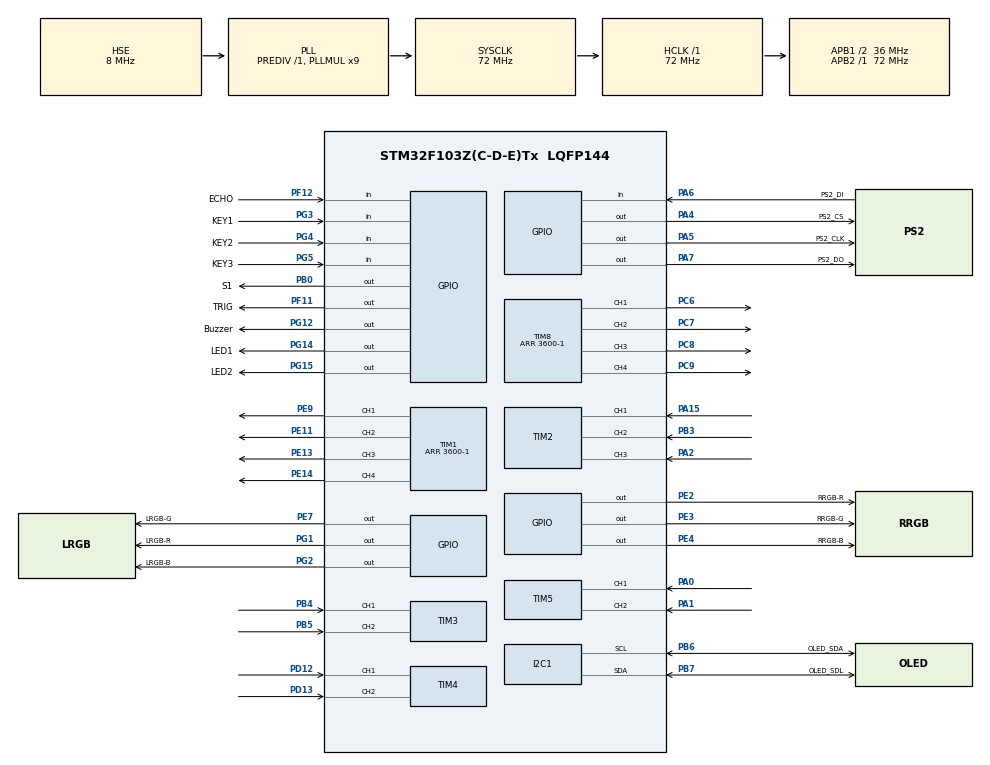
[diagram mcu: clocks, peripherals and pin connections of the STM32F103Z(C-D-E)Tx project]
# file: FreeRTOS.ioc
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ADC1.Channel-0\#ChannelRegularConversion=ADC_CHANNEL_TEMPSENSOR
ADC1.NbrOfConversionFlag=1
ADC1.Rank-0\#ChannelRegularConversion=1
ADC1.SamplingTime-0\#ChannelRegularConversion=ADC_SAMPLETIME_1CYCLE_5
ADC1.master=1
FREERTOS.Tasks01=defaultTask,0,128,StartDefaultTask,Default,NULL,Dynamic,NULL,NULL
FREERTOS.configTOTAL_HEAP_SIZE=20 * 1024
I2C1.I2C_Mode=I2C_Standard
Mcu.Family=STM32F1
Mcu.Name=STM32F103Z(C-D-E)Tx
Mcu.Package=LQFP144
NVIC.PriorityGroup=NVIC_PRIORITYGROUP_4
NVIC.TIM6_IRQn=true\:15\:0\:false\:false\:true\:false\:false\:true\:true
NVIC.TIM7_IRQn=true\:5\:0\:false\:false\:true\:true\:true\:true\:true
NVIC.TimeBase=TIM6_IRQn
NVIC.TimeBaseIP=TIM6
OSC_IN.Mode=HSE-External-Oscillator
OSC_IN.Signal=RCC_OSC_IN
OSC_OUT.Mode=HSE-External-Oscillator
OSC_OUT.Signal=RCC_OSC_OUT
PA0-WKUP.Signal=S_TIM5_CH1
PA1.Signal=S_TIM5_CH2
PA13.Mode=Serial_Wire
PA13.Signal=SYS_JTMS-SWDIO
PA14.Mode=Serial_Wire
PA14.Signal=SYS_JTCK-SWCLK
PA15.Signal=S_TIM2_CH1_ETR
PA2.Signal=S_TIM2_CH3
PA4.GPIO_Label=PS2_CS
PA4.GPIO_Speed=GPIO_SPEED_FREQ_MEDIUM
PA4.Signal=GPIO_Output
PA5.GPIO_Label=PS2_CLK
PA5.GPIO_Speed=GPIO_SPEED_FREQ_MEDIUM
PA5.PinState=GPIO_PIN_RESET
PA5.Signal=GPIO_Output
PA6.GPIO_Label=PS2_DI
PA6.Signal=GPIO_Input
PA7.GPIO_Label=PS2_DO
PA7.GPIO_Speed=GPIO_SPEED_FREQ_MEDIUM
PA7.Signal=GPIO_Output
PB0.GPIO_Label=S1
PB0.Signal=GPIO_Output
PB3.Signal=S_TIM2_CH2
PB4.Signal=S_TIM3_CH1
PB5.Signal=S_TIM3_CH2
PB6.GPIO_Label=OLED_SDA
PB6.Mode=I2C
PB6.Signal=I2C1_SCL
PB7.GPIO_Label=OLED_SDL
PB7.Mode=I2C
PB7.Signal=I2C1_SDA
PC6.Signal=S_TIM8_CH1
PC7.Signal=S_TIM8_CH2
PC8.Signal=S_TIM8_CH3
PC9.Signal=S_TIM8_CH4
PD12.Signal=S_TIM4_CH1
PD13.Signal=S_TIM4_CH2
PE11.Signal=S_TIM1_CH2
PE13.Signal=S_TIM1_CH3
PE14.Signal=S_TIM1_CH4
PE2.GPIO_Label=RRGB-R
PE2.Signal=GPIO_Output
PE3.GPIO_Label=RRGB-G
PE3.Signal=GPIO_Output
PE4.GPIO_Label=RRGB-B
PE4.Signal=GPIO_Output
PE7.GPIO_Label=LRGB-G
PE7.Signal=GPIO_Output
PE9.Signal=S_TIM1_CH1
PF11.GPIO_Label=TRIG
PF11.GPIO_Speed=GPIO_SPEED_FREQ_HIGH
PF11.PinState=GPIO_PIN_SET
PF11.Signal=GPIO_Output
PF12.GPIO_Label=ECHO
PF12.Signal=GPIO_Input
PG1.GPIO_Label=LRGB-R
PG1.Signal=GPIO_Output
PG12.GPIO_Label=Buzzer
PG12.Signal=GPIO_Output
PG14.GPIO_Label=LED1
PG14.Signal=GPIO_Output
PG15.GPIO_Label=LED2
PG15.Signal=GPIO_Output
PG2.GPIO_Label=LRGB-B
PG2.Signal=GPIO_Output
PG3.GPIO_Label=KEY1
PG3.Signal=GPIO_Input
PG4.GPIO_Label=KEY2
PG4.Signal=GPIO_Input
PG5.GPIO_Label=KEY3
PG5.Signal=GPIO_Input
ProjectManager.HeapSize=0x200
ProjectManager.StackSize=0x400
ProjectManager.TargetToolchain=STM32CubeIDE
RCC.AHBFreq_Value=72000000
RCC.APB1CLKDivider=RCC_HCLK_DIV2
RCC.APB1Freq_Value=36000000
RCC.APB1TimFreq_Value=72000000
RCC.APB2Freq_Value=72000000
RCC.APB2TimFreq_Value=72000000
RCC.HCLKFreq_Value=72000000
RCC.PLLMUL=RCC_PLL_MUL9
RCC.PLLSourceVirtual=RCC_PLLSOURCE_HSE
RCC.SYSCLKFreq_VALUE=72000000
RCC.SYSCLKSource=RCC_SYSCLKSOURCE_PLLCLK
RCC.USBFreq_Value=72000000
SH.S_TIM1_CH1.0=TIM1_CH1,PWM Generation1 CH1
SH.S_TIM1_CH2.0=TIM1_CH2,PWM Generation2 CH2
SH.S_TIM1_CH3.0=TIM1_CH3,PWM Generation3 CH3
SH.S_TIM1_CH4.0=TIM1_CH4,PWM Generation4 CH4
SH.S_TIM2_CH1_ETR.0=TIM2_CH1,Encoder_Interface
SH.S_TIM2_CH2.0=TIM2_CH2,Encoder_Interface
SH.S_TIM2_CH3.0=TIM2_CH3,Input_Capture3_from_TI3
SH.S_TIM3_CH1.0=TIM3_CH1,Encoder_Interface
SH.S_TIM3_CH2.0=TIM3_CH2,Encoder_Interface
SH.S_TIM4_CH1.0=TIM4_CH1,Encoder_Interface
SH.S_TIM4_CH2.0=TIM4_CH2,Encoder_Interface
SH.S_TIM5_CH1.0=TIM5_CH1,Encoder_Interface
SH.S_TIM5_CH2.0=TIM5_CH2,Encoder_Interface
SH.S_TIM8_CH1.0=TIM8_CH1,PWM Generation1 CH1
SH.S_TIM8_CH2.0=TIM8_CH2,PWM Generation2 CH2
SH.S_TIM8_CH3.0=TIM8_CH3,PWM Generation3 CH3
SH.S_TIM8_CH4.0=TIM8_CH4,PWM Generation4 CH4
TIM1.AutoReloadPreload=TIM_AUTORELOAD_PRELOAD_ENABLE
TIM1.Channel-PWM\ Generation1\ CH1=TIM_CHANNEL_1
TIM1.Channel-PWM\ Generation2\ CH2=TIM_CHANNEL_2
TIM1.Channel-PWM\ Generation3\ CH3=TIM_CHANNEL_3
TIM1.Channel-PWM\ Generation4\ CH4=TIM_CHANNEL_4
TIM1.Period=3600-1
TIM2.Channel-Input_Capture3_from_TI3=TIM_CHANNEL_3
TIM2.EncoderMode=TIM_ENCODERMODE_TI12
TIM3.EncoderMode=TIM_ENCODERMODE_TI12
TIM4.EncoderMode=TIM_ENCODERMODE_TI12
TIM5.EncoderMode=TIM_ENCODERMODE_TI12
TIM7.AutoReloadPreload=TIM_AUTORELOAD_PRELOAD_DISABLE
TIM7.Period=9
TIM7.Prescaler=71
TIM8.AutoReloadPreload=TIM_AUTORELOAD_PRELOAD_ENABLE
TIM8.Channel-PWM\ Generation1\ CH1=TIM_CHANNEL_1
TIM8.Channel-PWM\ Generation2\ CH2=TIM_CHANNEL_2
TIM8.Channel-PWM\ Generation3\ CH3=TIM_CHANNEL_3
TIM8.Channel-PWM\ Generation4\ CH4=TIM_CHANNEL_4
TIM8.Period=3600-1
VP_ADC1_TempSens_Input.Mode=IN-TempSens
VP_FREERTOS_VS_CMSIS_V1.Mode=CMSIS_V1
VP_SYS_VS_tim6.Mode=TIM6
VP_TIM1_VS_ClockSourceINT.Mode=Internal
VP_TIM7_VS_ClockSourceINT.Mode=Enable_Timer
VP_TIM8_VS_ClockSourceINT.Mode=Internal
board=custom

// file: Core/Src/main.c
/* USER CODE BEGIN Header */
/**
  ******************************************************************************
  * @file           : main.c
  * @brief          : Main program body
  * @author			: Sylvain Marchon
  ******************************************************************************
  */
/* USER CODE END Header */
#include "main.h"
#include "cmsis_os.h"
#include "adc.h"
#include "i2c.h"
#include "tim.h"
#include "gpio.h"

/* USER CODE BEGIN Includes */
#include "FreeRTOS.h"
#include "bsp.h"
/* USER CODE END Includes */

void SystemClock_Config(void);
void MX_FREERTOS_Init(void);

int main(void)
{

  /* MCU Configuration--------------------------------------------------------*/

  /* Reset of all peripherals, Initializes the Flash interface and the Systick. */
  HAL_Init();

  /* Configure the system clock */
  SystemClock_Config();

  /* Initialize all configured peripherals */
  MX_GPIO_Init();
  MX_I2C1_Init();
  MX_TIM7_Init();
  MX_TIM2_Init();
  MX_TIM3_Init();
  MX_TIM4_Init();
  MX_TIM5_Init();
  MX_TIM8_Init();
  MX_TIM1_Init();
  MX_ADC1_Init();
  /* USER CODE BEGIN 2 */
  BSP_Init();

  /* USER CODE END 2 */

  /* Call init function for freertos objects (in cmsis_os2.c) */
  MX_FREERTOS_Init();

  /* Start scheduler */
  osKernelStart();

  /* We should never get here as control is now taken by the scheduler */

  /* Infinite loop */
  /* USER CODE BEGIN WHILE */
  while (1)
  {

    /* USER CODE BEGIN 3 */
	/* USER CODE END 3 */
  }

    /* USER CODE END WHILE */

}

void SystemClock_Config(void)
{
  RCC_OscInitTypeDef RCC_OscInitStruct = {0};
  RCC_ClkInitTypeDef RCC_ClkInitStruct = {0};
  RCC_PeriphCLKInitTypeDef PeriphClkInit = {0};

  /** Initializes the RCC Oscillators according to the specified parameters
  * in the RCC_OscInitTypeDef structure.
  */
  RCC_OscInitStruct.OscillatorType = RCC_OSCILLATORTYPE_HSE;
  RCC_OscInitStruct.HSEState = RCC_HSE_ON;
  RCC_OscInitStruct.HSEPredivValue = RCC_HSE_PREDIV_DIV1;
  RCC_OscInitStruct.HSIState = RCC_HSI_ON;
  RCC_OscInitStruct.PLL.PLLState = RCC_PLL_ON;
  RCC_OscInitStruct.PLL.PLLSource = RCC_PLLSOURCE_HSE;
  RCC_OscInitStruct.PLL.PLLMUL = RCC_PLL_MUL9;
  if (HAL_RCC_OscConfig(&RCC_OscInitStruct) != HAL_OK)
  {
    Error_Handler();
  }

  /** Initializes the CPU, AHB and APB buses clocks
  */
  RCC_ClkInitStruct.ClockType = RCC_CLOCKTYPE_HCLK|RCC_CLOCKTYPE_SYSCLK
                              |RCC_CLOCKTYPE_PCLK1|RCC_CLOCKTYPE_PCLK2;
  RCC_ClkInitStruct.SYSCLKSource = RCC_SYSCLKSOURCE_PLLCLK;
  RCC_ClkInitStruct.AHBCLKDivider = RCC_SYSCLK_DIV1;
  RCC_ClkInitStruct.APB1CLKDivider = RCC_HCLK_DIV2;
  RCC_ClkInitStruct.APB2CLKDivider = RCC_HCLK_DIV1;

  if (HAL_RCC_ClockConfig(&RCC_ClkInitStruct, FLASH_LATENCY_2) != HAL_OK)
  {
    Error_Handler();
  }
  PeriphClkInit.PeriphClockSelection = RCC_PERIPHCLK_ADC;
  PeriphClkInit.AdcClockSelection = RCC_ADCPCLK2_DIV2;
  if (HAL_RCCEx_PeriphCLKConfig(&PeriphClkInit) != HAL_OK)
  {
    Error_Handler();
  }
}

void HAL_TIM_PeriodElapsedCallback(TIM_HandleTypeDef *htim)
{
  if (htim->Instance == TIM6) {
    HAL_IncTick();
  }
  /* USER CODE BEGIN Callback 1 */
	if (htim->Instance == TIM7)//10us
	{
		if (ultrasonic_flag)
		{
			ultrasonic_num++;
		}
		PwmServo_Handle();
	}
  /* USER CODE END Callback 1 */
}

void Error_Handler(void)
{
  __disable_irq();
  while (1)
  {
  }
}
